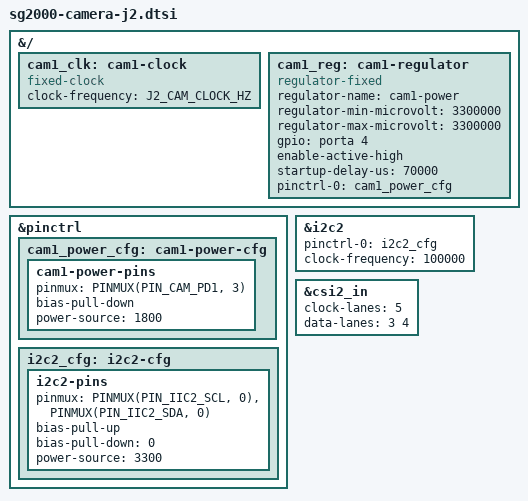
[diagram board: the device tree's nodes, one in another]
// SPDX-License-Identifier: (GPL-2.0 OR MIT)
/*
 * J2 part of the Milk-V Duo S camera overlays: power, I2C and the receiver
 * lanes. Each J2 overlay sets J2_CAM_CLOCK_HZ to its module's oscillator,
 * includes this file and adds the sensor under &i2c2 with its endpoint
 * labelled sensor_out. sg2000-camera.dtsi adds the CSI-2 receiver and the
 * VI capture block.
 *
 * J2 is wired like the Raspberry Pi 15-pin camera connector:
 *
 *   I2C2 (IIC2_SCL/IIC2_SDA, 3.3V)  the camera's control bus
 *   SENSOR_RSTN1 = CAM_PD1 = GPIOA4  the module's power enable (CAM_IO0)
 *   MIPI RX lanes 3/4 data, 5 clock  CSI-2 MAC 0, port 1 of the PHY
 *
 * Raspberry Pi camera modules carry their own oscillator, so CAM_MCLK1 is
 * unused.
 */

#include <dt-bindings/gpio/gpio.h>
#include <dt-bindings/pinctrl/pinctrl-sg2000.h>

#include "sg2000-camera.dtsi"

&{/} {
	cam1_clk: cam1-clock {
		compatible = "fixed-clock";
		#clock-cells = <0>;
		clock-frequency = <J2_CAM_CLOCK_HZ>;
	};

	cam1_reg: cam1-regulator {
		compatible = "regulator-fixed";
		regulator-name = "cam1-power";
		regulator-min-microvolt = <3300000>;
		regulator-max-microvolt = <3300000>;
		gpio = <&porta 4 GPIO_ACTIVE_HIGH>;
		enable-active-high;
		startup-delay-us = <70000>;
		pinctrl-names = "default";
		pinctrl-0 = <&cam1_power_cfg>;
	};
};

&pinctrl {
	cam1_power_cfg: cam1-power-cfg {
		cam1-power-pins {
			/* keep the pull-down: the camera stays off until driven */
			pinmux = <PINMUX(PIN_CAM_PD1, 3)>;
			bias-pull-down;
			power-source = <1800>;
		};
	};

	i2c2_cfg: i2c2-cfg {
		i2c2-pins {
			pinmux = <PINMUX(PIN_IIC2_SCL, 0)>,
				 <PINMUX(PIN_IIC2_SDA, 0)>;
			bias-pull-up;
			/* pull-up alone leaves PD as is; pinconf-generic warns, applies both */
			bias-pull-down = <0>;
			power-source = <3300>;
		};
	};
};

&i2c2 {
	#address-cells = <1>;
	#size-cells = <0>;
	pinctrl-names = "default";
	pinctrl-0 = <&i2c2_cfg>;
	/*
	 * J2's I2C goes through a UM3204H auto-direction level shifter. On a
	 * 500 mm cable SCL's rising edge crawls up to the shifter's one-shot
	 * threshold with tens-of-MHz ringing on top and crosses it more than
	 * once, so the sensor counts extra clocks and transfers fail at random
	 * at any bus speed. Use a short (<= 150 mm) cable.
	 */
	clock-frequency = <100000>;
	status = "okay";
};

&csi2_in {
	clock-lanes = <5>;
	data-lanes = <3 4>;
};
